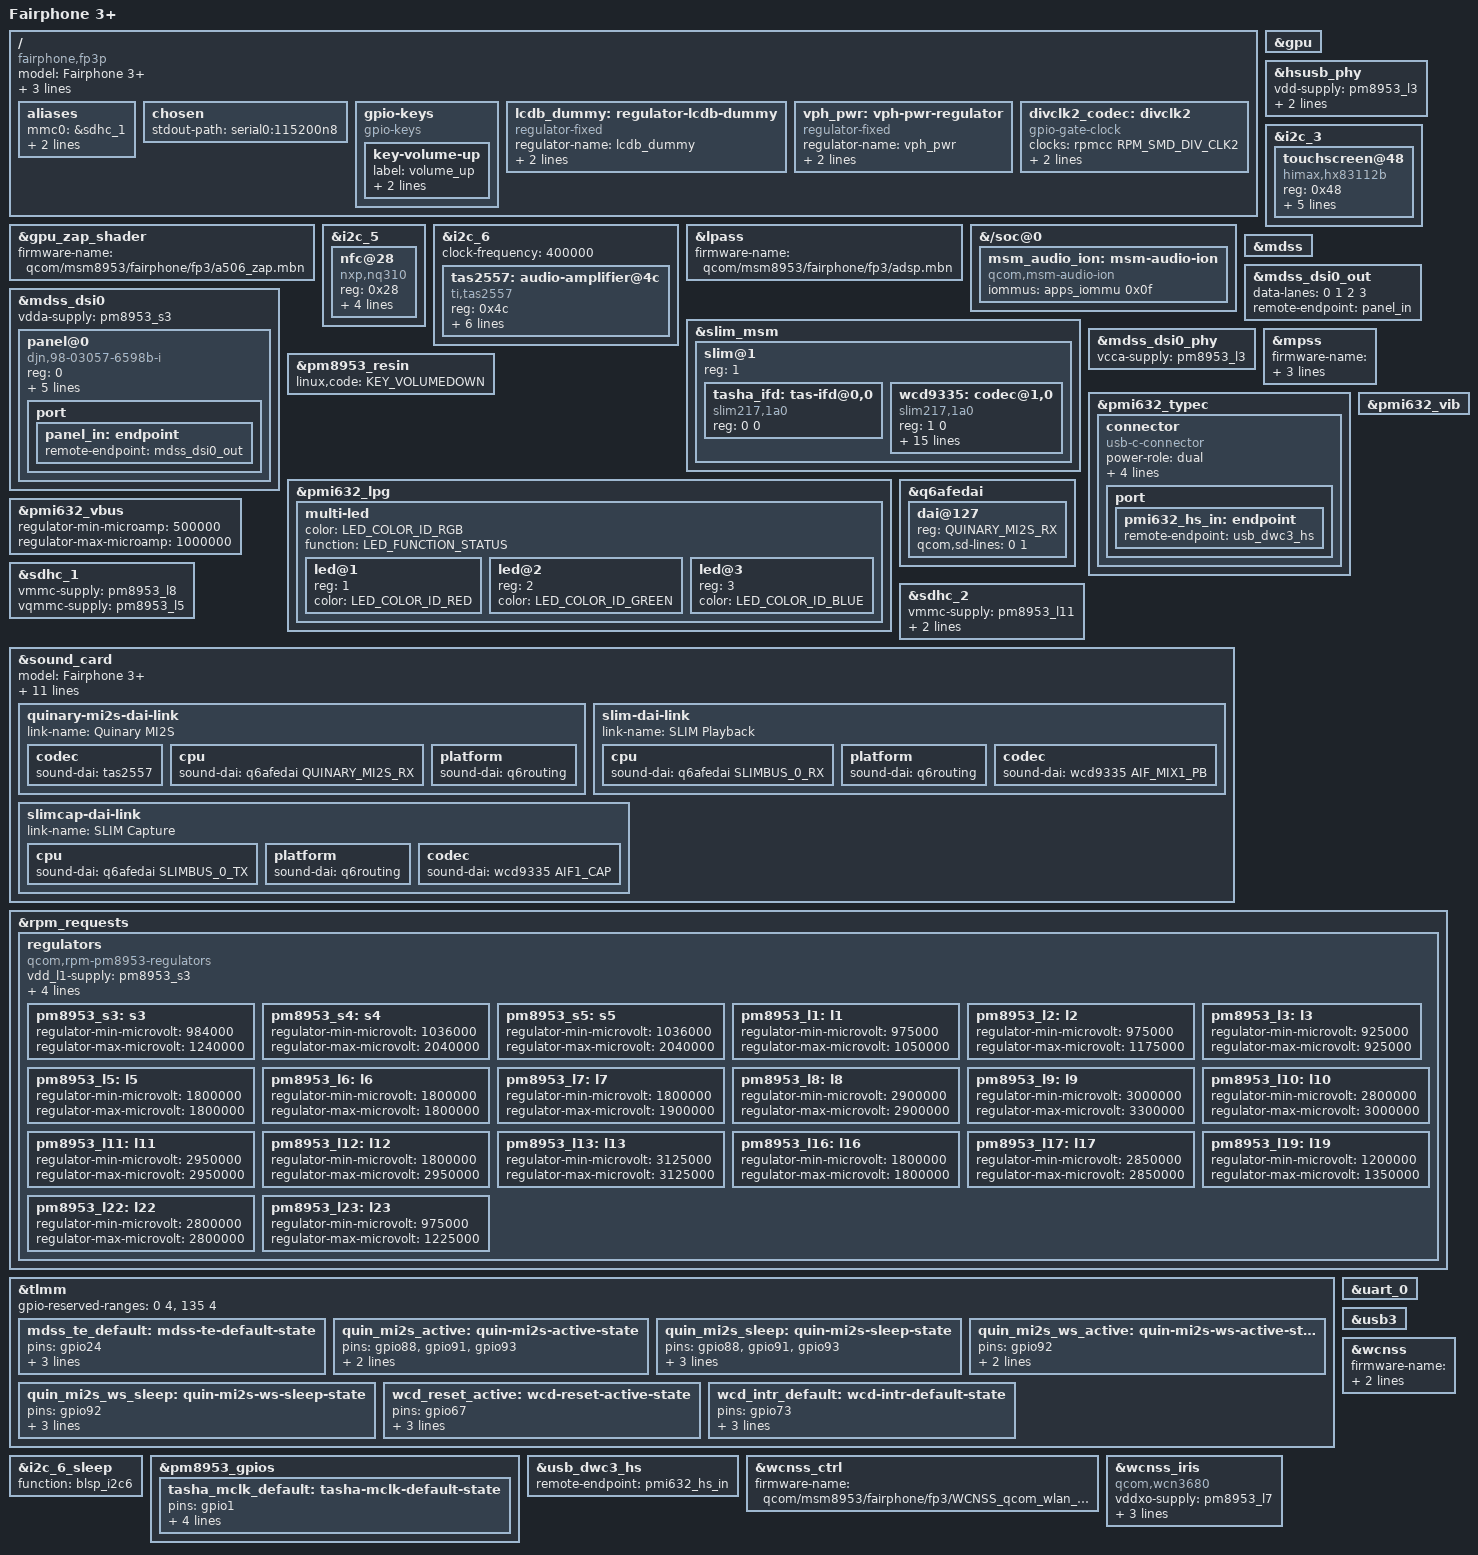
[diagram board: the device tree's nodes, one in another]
// SPDX-License-Identifier: BSD-3-Clause
/*
 * Copyright (c) 2022, Luca Weiss <luca@z3ntu.xyz>
 * Copyright (c) 2025, Marc Lainez <marc.lainez@gmail.com>
 *
 * Device tree for Fairphone 3+ (FP3+).
 *
 * The FP3+ is a hardware revision of the Fairphone 3 with a different
 * speaker amplifier (TI TAS2557 instead of Awinic AW8898) and upgraded
 * camera modules.
 */
/dts-v1/;

#include <dt-bindings/leds/common.h>
#include <dt-bindings/pinctrl/qcom,pmic-gpio.h>
#include <dt-bindings/sound/qcom,wcd9335.h>
#include "sdm632.dtsi"
#include "pm8953.dtsi"
#include "pmi632.dtsi"

/ {
	model = "Fairphone 3+";
	compatible = "fairphone,fp3p", "fairphone,fp3", "qcom,sdm632";
	chassis-type = "handset";
	qcom,msm-id = <349 0>;
	qcom,board-id = <8 0x10000>;

	aliases {
		mmc0 = &sdhc_1;
		mmc1 = &sdhc_2;
		serial0 = &uart_0;
	};

	chosen {
		stdout-path = "serial0:115200n8";
	};

	gpio-keys {
		compatible = "gpio-keys";

		key-volume-up {
			label = "volume_up";
			linux,code = <KEY_VOLUMEUP>;
			gpios = <&tlmm 85 GPIO_ACTIVE_LOW>;
		};
	};

	/* Dummy regulator until PMI632 has LCDB VSP/VSN support */
	lcdb_dummy: regulator-lcdb-dummy {
		compatible = "regulator-fixed";
		regulator-name = "lcdb_dummy";
		regulator-min-microvolt = <5500000>;
		regulator-max-microvolt = <5500000>;
	};

	vph_pwr: vph-pwr-regulator {
		compatible = "regulator-fixed";
		regulator-name = "vph_pwr";
		regulator-always-on;
		regulator-boot-on;
	};

	divclk2_codec: divclk2 {
		compatible = "gpio-gate-clock";
		clocks = <&rpmcc RPM_SMD_DIV_CLK2>;
		#clock-cells = <0>;
		enable-gpios = <&pm8953_gpios 1 GPIO_ACTIVE_HIGH>;
		pinctrl-names = "default";
		pinctrl-0 = <&tasha_mclk_default>;
	};
};

&gpu {
	status = "okay";
};

&gpu_zap_shader {
	firmware-name = "qcom/msm8953/fairphone/fp3/a506_zap.mbn";
};

&hsusb_phy {
	vdd-supply = <&pm8953_l3>;
	vdda-pll-supply = <&pm8953_l7>;
	vdda-phy-dpdm-supply = <&pm8953_l13>;

	status = "okay";
};

&i2c_3 {
	status = "okay";

	touchscreen@48 {
		compatible = "himax,hx83112b";
		reg = <0x48>;
		interrupt-parent = <&tlmm>;
		interrupts = <65 IRQ_TYPE_LEVEL_LOW>;
		touchscreen-size-x = <1080>;
		touchscreen-size-y = <2160>;
		reset-gpios = <&tlmm 64 GPIO_ACTIVE_LOW>;
	};
};

&i2c_5 {
	status = "okay";

	nfc@28 {
		compatible = "nxp,nq310", "nxp,nxp-nci-i2c";
		reg = <0x28>;

		interrupt-parent = <&tlmm>;
		interrupts = <17 IRQ_TYPE_LEVEL_HIGH>;

		enable-gpios = <&tlmm 16 GPIO_ACTIVE_HIGH>;
		firmware-gpios = <&tlmm 62 GPIO_ACTIVE_HIGH>;
	};
};

&i2c_6 {
	status = "okay";
	clock-frequency = <400000>;

	tas2557: audio-amplifier@4c {
		compatible = "ti,tas2557";
		reg = <0x4c>;

		shutdown-gpios = <&tlmm 21 GPIO_ACTIVE_HIGH>;
		interrupts-extended = <&tlmm 20 IRQ_TYPE_LEVEL_HIGH>;

		dvdd-supply = <&pm8953_l5>;
		vddio-supply = <&pm8953_l5>;
		vdd-supply = <&vph_pwr>;

		#sound-dai-cells = <0>;
	};
};

&lpass {
	firmware-name = "qcom/msm8953/fairphone/fp3/adsp.mbn";

	status = "okay";
};

/* Audio ION: IOMMU context for sharing cal memory with ADSP */
&{/soc@0} {
	msm_audio_ion: msm-audio-ion {
		compatible = "qcom,msm-audio-ion";
		iommus = <&apps_iommu 0x0f>;
	};
};

&slim_msm {
	status = "okay";

	slim@1 {
		reg = <1>;
		#address-cells = <2>;
		#size-cells = <0>;

		tasha_ifd: tas-ifd@0,0 {
			compatible = "slim217,1a0";
			reg = <0 0>;
		};

		wcd9335: codec@1,0 {
			compatible = "slim217,1a0";
			reg = <1 0>;

			clock-names = "mclk", "slimbus";
			clocks = <&divclk2_codec>,
				 <&rpmcc RPM_SMD_BB_CLK1>;

			interrupt-parent = <&tlmm>;
			interrupts = <73 IRQ_TYPE_LEVEL_HIGH>,
				     <73 IRQ_TYPE_LEVEL_HIGH>;
			interrupt-names = "intr1", "intr2";
			interrupt-controller;
			#interrupt-cells = <1>;

			pinctrl-0 = <&wcd_reset_active &wcd_intr_default>;
			pinctrl-names = "default";

			reset-gpios = <&tlmm 67 GPIO_ACTIVE_LOW>;
			slim-ifc-dev = <&tasha_ifd>;

			#sound-dai-cells = <1>;

			vdd-buck-supply = <&pm8953_l5>;
			vdd-buck-sido-supply = <&pm8953_l5>;
			vdd-rx-supply = <&pm8953_l5>;
			vdd-tx-supply = <&pm8953_l5>;
			vdd-io-supply = <&pm8953_l5>;
			vdd-vbat-supply = <&vph_pwr>;
			vdd-micbias-supply = <&pm8953_l13>;
		};
	};
};

&mdss {
	status = "okay";
};

&mdss_dsi0 {
	vdda-supply = <&pm8953_s3>;
	status = "okay";

	panel@0 {
		compatible = "djn,98-03057-6598b-i";
		reg = <0>;

		reset-gpios = <&tlmm 61 GPIO_ACTIVE_LOW>;

		iovcc-supply = <&pm8953_l6>;
		vsn-supply = <&lcdb_dummy>;
		vsp-supply = <&lcdb_dummy>;

		pinctrl-0 = <&mdss_te_default>;
		pinctrl-names = "default";

		port {
			panel_in: endpoint {
				remote-endpoint = <&mdss_dsi0_out>;
			};
		};
	};
};

&mdss_dsi0_out {
	data-lanes = <0 1 2 3>;
	remote-endpoint = <&panel_in>;
};

&mdss_dsi0_phy {
	vcca-supply = <&pm8953_l3>;
	status = "okay";
};

&mpss {
	firmware-name = "qcom/msm8953/fairphone/fp3/mba.mbn",
			"qcom/msm8953/fairphone/fp3/modem.mbn";
	pll-supply = <&pm8953_l7>;

	status = "okay";
};

&pm8953_resin {
	linux,code = <KEY_VOLUMEDOWN>;
	status = "okay";
};

&pmi632_lpg {
	status = "okay";

	multi-led {
		color = <LED_COLOR_ID_RGB>;
		function = LED_FUNCTION_STATUS;

		#address-cells = <1>;
		#size-cells = <0>;

		led@1 {
			reg = <1>;
			color = <LED_COLOR_ID_RED>;
		};

		led@2 {
			reg = <2>;
			color = <LED_COLOR_ID_GREEN>;
		};

		led@3 {
			reg = <3>;
			color = <LED_COLOR_ID_BLUE>;
		};
	};
};

&pmi632_typec {
	status = "okay";

	connector {
		compatible = "usb-c-connector";

		power-role = "dual";
		data-role = "dual";
		self-powered;

		typec-power-opmode = "default";
		pd-disable;

		port {
			pmi632_hs_in: endpoint {
				remote-endpoint = <&usb_dwc3_hs>;
			};
		};
	};
};

&pmi632_vbus {
	regulator-min-microamp = <500000>;
	regulator-max-microamp = <1000000>;
	status = "okay";
};

&pmi632_vib {
	status = "okay";
};

&q6afedai {
	dai@127 {
		reg = <QUINARY_MI2S_RX>;
		qcom,sd-lines = <0 1>;
	};
};

&sdhc_1 {
	vmmc-supply = <&pm8953_l8>;
	vqmmc-supply = <&pm8953_l5>;

	status = "okay";
};

&sdhc_2 {
	vmmc-supply = <&pm8953_l11>;
	vqmmc-supply = <&pm8953_l12>;

	cd-gpios = <&tlmm 133 GPIO_ACTIVE_LOW>;

	status = "okay";
};

&sound_card {
	model = "Fairphone 3+";

	pinctrl-0 = <&quin_mi2s_active>, <&quin_mi2s_ws_active>;
	pinctrl-1 = <&quin_mi2s_sleep>, <&quin_mi2s_ws_sleep>;
	pinctrl-names = "default",
			"sleep";

	status = "okay";

	/* FP3+ does not use the codec on PM8953 */
	/delete-property/ audio-routing;

	audio-routing = "Speaker", "OUT",
			"RX_BIAS", "MCLK",
			"AMIC2", "MIC BIAS2",
			"AMIC5", "MIC BIAS3",
			"AMIC5", "Handset Mic",
			"AMIC2", "Headset Mic",
			"Headphone Jack", "HPHL",
			"Headphone Jack", "HPHR",
			"Earpiece", "EAR",
			"DMIC1", "Digital Mic1",
			"DMIC2", "Digital Mic2";
	widgets = "Speaker", "Speaker",
		  "Speaker", "Earpiece";
	pin-switches = "Speaker", "Earpiece";

	/delete-node/ primary-mi2s-dai-link;
	/delete-node/ tertiary-mi2s-dai-link;

	quinary-mi2s-dai-link {
		link-name = "Quinary MI2S";

		codec {
			sound-dai = <&tas2557>;
		};

		cpu {
			sound-dai = <&q6afedai QUINARY_MI2S_RX>;
		};

		platform {
			sound-dai = <&q6routing>;
		};
	};

	slim-dai-link {
		link-name = "SLIM Playback";

		cpu {
			sound-dai = <&q6afedai SLIMBUS_0_RX>;
		};

		platform {
			sound-dai = <&q6routing>;
		};

		codec {
			sound-dai = <&wcd9335 AIF_MIX1_PB>;
		};
	};

	slimcap-dai-link {
		link-name = "SLIM Capture";

		cpu {
			sound-dai = <&q6afedai SLIMBUS_0_TX>;
		};

		platform {
			sound-dai = <&q6routing>;
		};

		codec {
			sound-dai = <&wcd9335 AIF1_CAP>;
		};
	};
};

&rpm_requests {
	regulators {
		compatible = "qcom,rpm-pm8953-regulators";

		vdd_l1-supply = <&pm8953_s3>;
		vdd_l2_l3-supply = <&pm8953_s3>;
		vdd_l4_l5_l6_l7_l16_l19-supply = <&pm8953_s4>;
		vdd_l8_l11_l12_l13_l14_l15-supply = <&vph_pwr>;
		vdd_l9_l10_l17_l18_l22-supply = <&vph_pwr>;

		pm8953_s3: s3 {
			regulator-min-microvolt = <984000>;
			regulator-max-microvolt = <1240000>;
		};

		pm8953_s4: s4 {
			regulator-min-microvolt = <1036000>;
			regulator-max-microvolt = <2040000>;
		};

		pm8953_s5: s5 {
			regulator-min-microvolt = <1036000>;
			regulator-max-microvolt = <2040000>;
		};

		pm8953_l1: l1 {
			regulator-min-microvolt = <975000>;
			regulator-max-microvolt = <1050000>;
		};

		pm8953_l2: l2 {
			regulator-min-microvolt = <975000>;
			regulator-max-microvolt = <1175000>;
		};

		pm8953_l3: l3 {
			regulator-min-microvolt = <925000>;
			regulator-max-microvolt = <925000>;
		};

		pm8953_l5: l5 {
			regulator-min-microvolt = <1800000>;
			regulator-max-microvolt = <1800000>;
		};

		pm8953_l6: l6 {
			regulator-min-microvolt = <1800000>;
			regulator-max-microvolt = <1800000>;
		};

		pm8953_l7: l7 {
			regulator-min-microvolt = <1800000>;
			regulator-max-microvolt = <1900000>;
		};

		pm8953_l8: l8 {
			regulator-min-microvolt = <2900000>;
			regulator-max-microvolt = <2900000>;
		};

		pm8953_l9: l9 {
			regulator-min-microvolt = <3000000>;
			regulator-max-microvolt = <3300000>;
		};

		pm8953_l10: l10 {
			regulator-min-microvolt = <2800000>;
			regulator-max-microvolt = <3000000>;
		};

		pm8953_l11: l11 {
			regulator-min-microvolt = <2950000>;
			regulator-max-microvolt = <2950000>;
		};

		pm8953_l12: l12 {
			regulator-min-microvolt = <1800000>;
			regulator-max-microvolt = <2950000>;
		};

		pm8953_l13: l13 {
			regulator-min-microvolt = <3125000>;
			regulator-max-microvolt = <3125000>;
		};

		pm8953_l16: l16 {
			regulator-min-microvolt = <1800000>;
			regulator-max-microvolt = <1800000>;
		};

		pm8953_l17: l17 {
			regulator-min-microvolt = <2850000>;
			regulator-max-microvolt = <2850000>;
		};

		pm8953_l19: l19 {
			regulator-min-microvolt = <1200000>;
			regulator-max-microvolt = <1350000>;
		};

		pm8953_l22: l22 {
			regulator-min-microvolt = <2800000>;
			regulator-max-microvolt = <2800000>;
		};

		pm8953_l23: l23 {
			regulator-min-microvolt = <975000>;
			regulator-max-microvolt = <1225000>;
		};
	};
};

&tlmm {
	/*
	 * 0-3: unused but protected by TZ
	 * 135-138: fingerprint reader (SPI)
	 */
	gpio-reserved-ranges = <0 4>, <135 4>;

	mdss_te_default: mdss-te-default-state {
		pins = "gpio24";
		function = "mdp_vsync";
		drive-strength = <2>;
		bias-pull-down;
	};

	quin_mi2s_active: quin-mi2s-active-state {
		pins = "gpio88", "gpio91", "gpio93";
		function = "pri_mi2s";
		drive-strength = <8>;
	};

	quin_mi2s_sleep: quin-mi2s-sleep-state {
		pins = "gpio88", "gpio91", "gpio93";
		function = "pri_mi2s";
		drive-strength = <2>;
		bias-pull-down;
	};

	quin_mi2s_ws_active: quin-mi2s-ws-active-state {
		pins = "gpio92";
		function = "pri_mi2s_ws";
		drive-strength = <8>;
	};

	quin_mi2s_ws_sleep: quin-mi2s-ws-sleep-state {
		pins = "gpio92";
		function = "pri_mi2s_ws";
		drive-strength = <2>;
		bias-pull-down;
	};

	wcd_reset_active: wcd-reset-active-state {
		pins = "gpio67";
		function = "gpio";
		drive-strength = <16>;
		output-high;
	};

	wcd_intr_default: wcd-intr-default-state {
		pins = "gpio73";
		function = "gpio";
		drive-strength = <2>;
		bias-pull-down;
	};
};

/*
 * Override I2C bus 6 sleep state: keep blsp_i2c6 function instead of
 * switching to GPIO mode, which kills communication with TAS2557.
 */
&i2c_6_sleep {
	function = "blsp_i2c6";
};

&pm8953_gpios {
	tasha_mclk_default: tasha-mclk-default-state {
		pins = "gpio1";
		function = "func1";
		bias-disable;
		power-source = <0>;
		qcom,drive-strength = <PMIC_GPIO_STRENGTH_LOW>;
	};
};

&uart_0 {
	status = "okay";
};

&usb3 {
	status = "okay";
};

&usb_dwc3_hs {
	remote-endpoint = <&pmi632_hs_in>;
};

&wcnss {
	firmware-name = "qcom/msm8953/fairphone/fp3/wcnss.mbn";
	vddpx-supply = <&pm8953_l5>;

	status = "okay";
};

&wcnss_ctrl {
	firmware-name = "qcom/msm8953/fairphone/fp3/WCNSS_qcom_wlan_nv.bin";
};

&wcnss_iris {
	compatible = "qcom,wcn3680";

	vddxo-supply = <&pm8953_l7>;
	vddrfa-supply = <&pm8953_l19>;
	vddpa-supply = <&pm8953_l9>;
	vdddig-supply = <&pm8953_l5>;
};
